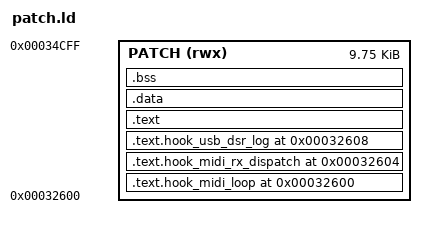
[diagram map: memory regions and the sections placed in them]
/* Auto-generated by hook_framework.py — do not edit manually. */

INCLUDE "/home/florian/src-misc/helicon-blender/firmware/firmware_symbols.ld"

ENTRY(_hook_midi_loop_stub)

MEMORY {
    PATCH (rwx) : ORIGIN = 0x32600, LENGTH = 9984
}

SECTIONS {
    .text.hook_midi_loop 0x32600 : {
        *(.text.hook_midi_loop)
    } > PATCH

    .text.hook_midi_rx_dispatch 0x32604 : {
        *(.text.hook_midi_rx_dispatch)
    } > PATCH

    .text.hook_usb_dsr_log 0x32608 : {
        *(.text.hook_usb_dsr_log)
    } > PATCH

    .text : {
        *(.text*)
        *(.rodata*)
    } > PATCH

    .data : {
        *(.data*)
    } > PATCH

    .bss : {
        *(.bss*)
        *(COMMON)
    } > PATCH

    /DISCARD/ : {
        *(.ARM.attributes)
        *(.ARM.exidx*)
        *(.comment)
    }
}
